VERSION ""

NS_ :

BS_:

BU_: EBCM EON CAM RADAR PCM EPS VSA SCM BDY XXX EPB

BO_ 314 THROTTLE: 8 PCM
 SG_ THROTTLE_PEDAL : 15|8@0+ (1,0) [0|255] ""  EON

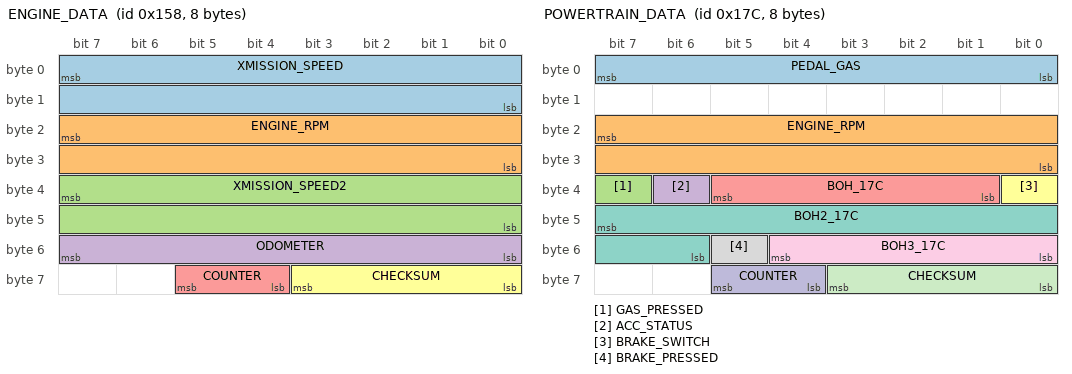
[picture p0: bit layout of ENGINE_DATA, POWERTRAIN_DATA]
BO_ 344 ENGINE_DATA: 8 PCM
 SG_ XMISSION_SPEED : 7|16@0+ (0.01,0) [0|250] "kph"  EON
 SG_ ENGINE_RPM : 23|16@0+ (1,0) [0|15000] "rpm"  EON
 SG_ XMISSION_SPEED2 : 39|16@0+ (0.01,0) [0|250] "kph"  EON
 SG_ ODOMETER : 55|8@0+ (10,0) [0|2550] "m"  XXX
 SG_ COUNTER : 61|2@0+ (1,0) [0|3] ""  EON
 SG_ CHECKSUM : 59|4@0+ (1,0) [0|15] ""  EON

BO_ 380 POWERTRAIN_DATA: 8 PCM
 SG_ PEDAL_GAS : 7|8@0+ (1,0) [0|255] ""  EON
 SG_ ENGINE_RPM : 23|16@0+ (1,0) [0|15000] "rpm"  EON
 SG_ GAS_PRESSED : 39|1@0+ (1,0) [0|1] ""  EON
 SG_ ACC_STATUS : 38|1@0+ (1,0) [0|1] ""  EON
 SG_ BOH_17C : 37|5@0+ (1,0) [0|1] ""  EON
 SG_ BRAKE_SWITCH : 32|1@0+ (1,0) [0|1] ""  EON
 SG_ BOH2_17C : 47|10@0+ (1,0) [0|1] ""  EON
 SG_ BRAKE_PRESSED : 53|1@0+ (1,0) [0|1] ""  EON
 SG_ BOH3_17C : 52|5@0+ (1,0) [0|1] ""  EON
 SG_ COUNTER : 61|2@0+ (1,0) [0|3] ""  EON
 SG_ CHECKSUM : 59|4@0+ (1,0) [0|15] ""  EON

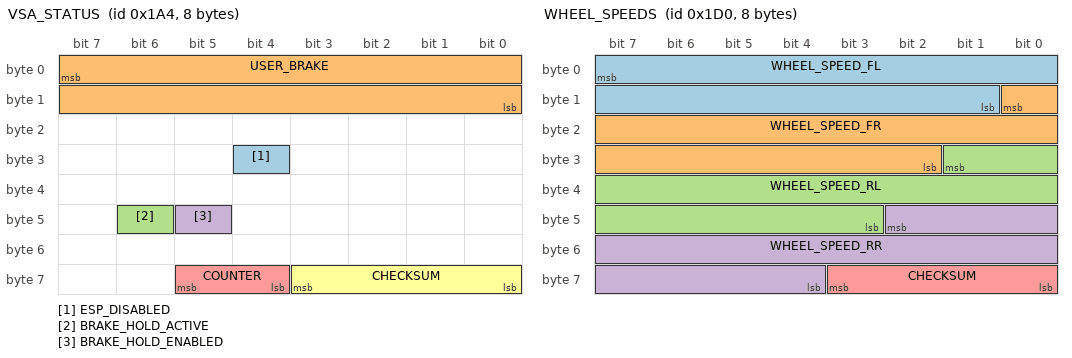
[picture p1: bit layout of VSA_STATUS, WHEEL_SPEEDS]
BO_ 420 VSA_STATUS: 8 VSA
 SG_ ESP_DISABLED : 28|1@0+ (1,0) [0|1] ""  EON
 SG_ USER_BRAKE : 7|16@0+ (0.015625,-1.609375) [0|1000] ""  EON
 SG_ BRAKE_HOLD_ACTIVE : 46|1@0+ (1,0) [0|1] ""  EON
 SG_ BRAKE_HOLD_ENABLED : 45|1@0+ (1,0) [0|1] ""  EON
 SG_ COUNTER : 61|2@0+ (1,0) [0|3] ""  EON
 SG_ CHECKSUM : 59|4@0+ (1,0) [0|15] ""  EON

BO_ 464 WHEEL_SPEEDS: 8 VSA
 SG_ WHEEL_SPEED_FL : 7|15@0+ (0.01,0) [0|250] "kph"  EON
 SG_ WHEEL_SPEED_FR : 8|15@0+ (0.01,0) [0|250] "kph"  EON
 SG_ WHEEL_SPEED_RL : 25|15@0+ (0.01,0) [0|250] "kph"  EON
 SG_ WHEEL_SPEED_RR : 42|15@0+ (0.01,0) [0|250] "kph"  EON
 SG_ CHECKSUM : 59|4@0+ (1,0) [0|3] ""  EON

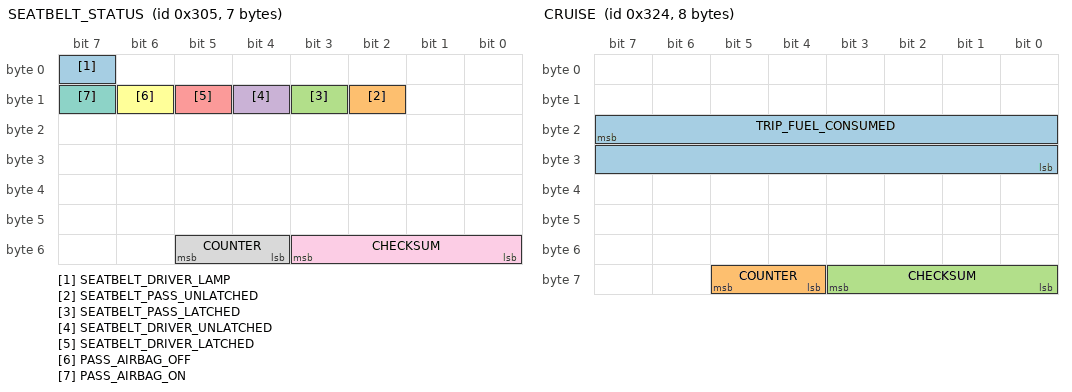
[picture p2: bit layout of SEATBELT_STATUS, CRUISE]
BO_ 773 SEATBELT_STATUS: 7 BDY
 SG_ SEATBELT_DRIVER_LAMP : 7|1@0+ (1,0) [0|1] ""  EON
 SG_ SEATBELT_PASS_UNLATCHED : 10|1@0+ (1,0) [0|1] ""  EON
 SG_ SEATBELT_PASS_LATCHED : 11|1@0+ (1,0) [0|1] ""  EON
 SG_ SEATBELT_DRIVER_UNLATCHED : 12|1@0+ (1,0) [0|1] ""  EON
 SG_ SEATBELT_DRIVER_LATCHED : 13|1@0+ (1,0) [0|1] ""  EON
 SG_ PASS_AIRBAG_OFF : 14|1@0+ (1,0) [0|1] ""  EON
 SG_ PASS_AIRBAG_ON : 15|1@0+ (1,0) [0|1] ""  EON
 SG_ COUNTER : 53|2@0+ (1,0) [0|3] ""  EON
 SG_ CHECKSUM : 51|4@0+ (1,0) [0|3] ""  EON

BO_ 804 CRUISE: 8 PCM
 SG_ TRIP_FUEL_CONSUMED : 23|16@0+ (1,0) [0|255] ""  EON
 SG_ COUNTER : 61|2@0+ (1,0) [0|3] ""  EON
 SG_ CHECKSUM : 59|4@0+ (1,0) [0|15] ""  EON

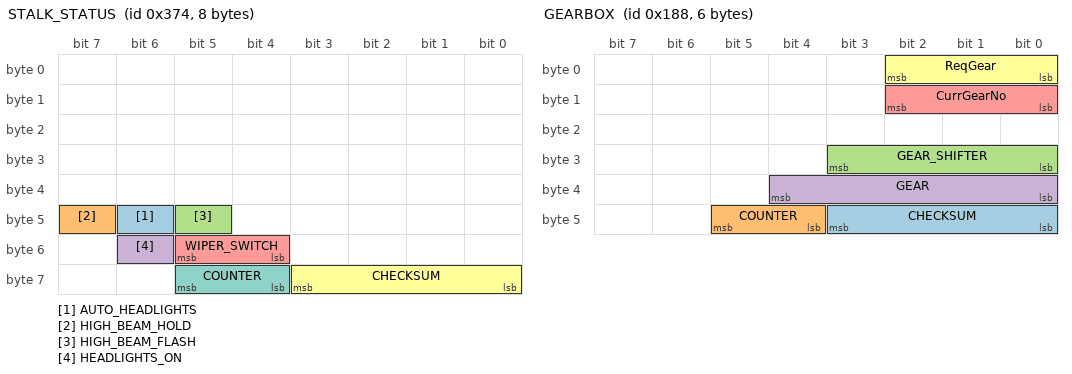
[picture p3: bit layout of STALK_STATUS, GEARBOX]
BO_ 884 STALK_STATUS: 8 XXX
 SG_ AUTO_HEADLIGHTS : 46|1@0+ (1,0) [0|1] ""  EON
 SG_ HIGH_BEAM_HOLD : 47|1@0+ (1,0) [0|1] ""  EON
 SG_ HIGH_BEAM_FLASH : 45|1@0+ (1,0) [0|1] ""  EON
 SG_ HEADLIGHTS_ON : 54|1@0+ (1,0) [0|1] ""  EON
 SG_ WIPER_SWITCH : 53|2@0+ (1,0) [0|3] ""  XXX
 SG_ CHECKSUM : 59|4@0+ (1,0) [0|3] ""  EON
 SG_ COUNTER : 61|2@0+ (1,0) [0|3] ""  EON

BO_ 392 GEARBOX: 6 XXX
 SG_ CHECKSUM : 43|4@0+ (1,0) [0|15] ""  XXX
 SG_ COUNTER : 45|2@0+ (1,0) [0|3] ""  XXX
 SG_ GEAR_SHIFTER : 27|4@0+ (1,0) [0|15] ""  EON
 SG_ GEAR : 36|5@0+ (1,0) [0|31] ""  EON
 SG_ CurrGearNo : 10|3@0+ (1,0) [0|7] "" Vector__XXX
 SG_ ReqGear : 2|3@0+ (1,0) [0|7] "" Vector__XXX

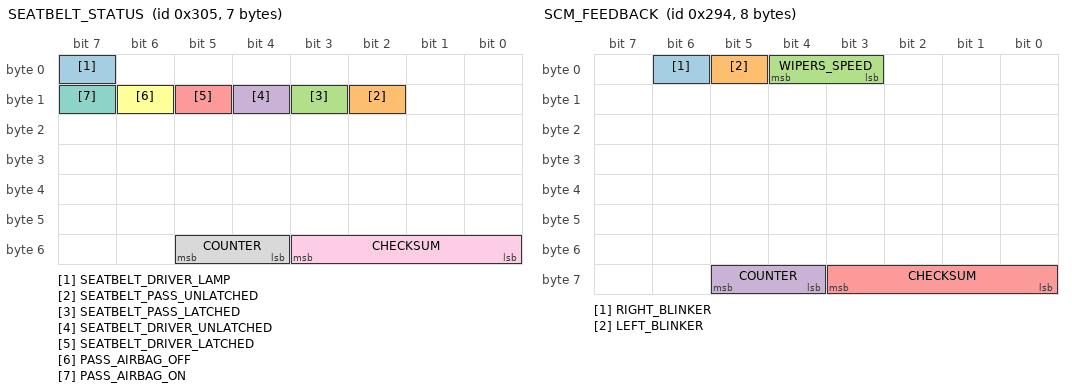
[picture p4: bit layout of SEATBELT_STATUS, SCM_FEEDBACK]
BO_ 773 SEATBELT_STATUS: 7 BDY
 SG_ SEATBELT_DRIVER_LAMP : 7|1@0+ (1,0) [0|1] ""  EON
 SG_ SEATBELT_PASS_UNLATCHED : 10|1@0+ (1,0) [0|1] ""  EON
 SG_ SEATBELT_PASS_LATCHED : 11|1@0+ (1,0) [0|1] ""  EON
 SG_ SEATBELT_DRIVER_UNLATCHED : 12|1@0+ (1,0) [0|1] ""  EON
 SG_ SEATBELT_DRIVER_LATCHED : 13|1@0+ (1,0) [0|1] ""  EON
 SG_ PASS_AIRBAG_OFF : 14|1@0+ (1,0) [0|1] ""  EON
 SG_ PASS_AIRBAG_ON : 15|1@0+ (1,0) [0|1] ""  EON
 SG_ COUNTER : 53|2@0+ (1,0) [0|3] ""  EON
 SG_ CHECKSUM : 51|4@0+ (1,0) [0|3] ""  EON

BO_ 660 SCM_FEEDBACK: 8 SCM
 SG_ RIGHT_BLINKER : 6|1@0+ (1,0) [0|1] ""  EON
 SG_ LEFT_BLINKER : 5|1@0+ (1,0) [0|1] ""  EON
 SG_ WIPERS_SPEED : 4|2@0+ (1,0) [0|3] ""  EON
 SG_ COUNTER : 61|2@0+ (1,0) [0|3] ""  EON
 SG_ CHECKSUM : 59|4@0+ (1,0) [0|15] ""  EON

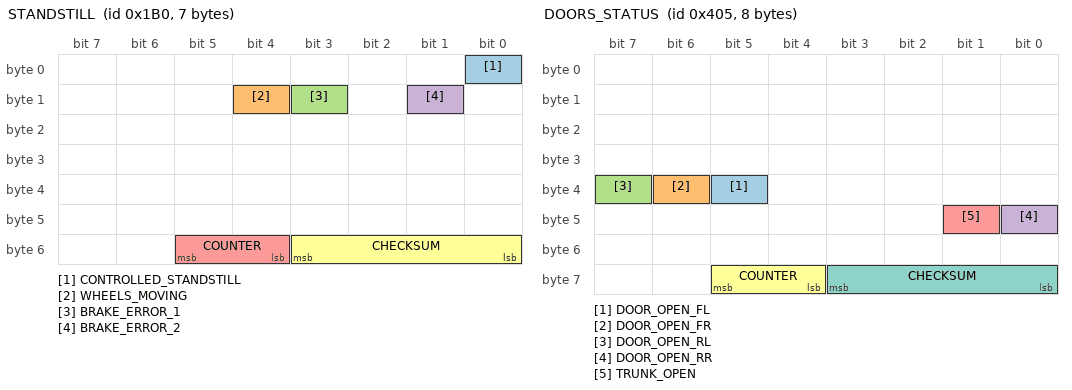
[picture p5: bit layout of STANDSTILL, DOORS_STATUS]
BO_ 432 STANDSTILL: 7 VSA
 SG_ CONTROLLED_STANDSTILL : 0|1@0+ (1,0) [0|1] ""  EON
 SG_ WHEELS_MOVING : 12|1@0+ (1,0) [0|1] ""  EON
 SG_ BRAKE_ERROR_1 : 11|1@0+ (1,0) [0|1] ""  EON
 SG_ BRAKE_ERROR_2 : 9|1@0+ (1,0) [0|1] ""  EON
 SG_ COUNTER : 53|2@0+ (1,0) [0|3] ""  EON
 SG_ CHECKSUM : 51|4@0+ (1,0) [0|3] ""  EON

BO_ 1029 DOORS_STATUS: 8 BDY
 SG_ DOOR_OPEN_FL : 37|1@0+ (1,0) [0|1] ""  EON
 SG_ DOOR_OPEN_FR : 38|1@0+ (1,0) [0|1] ""  EON
 SG_ DOOR_OPEN_RL : 39|1@0+ (1,0) [0|1] ""  EON
 SG_ DOOR_OPEN_RR : 40|1@0+ (1,0) [0|1] ""  EON
 SG_ TRUNK_OPEN : 41|1@0+ (1,0) [0|1] ""  EON
 SG_ COUNTER : 61|2@0+ (1,0) [0|3] ""  EON
 SG_ CHECKSUM : 59|4@0+ (1,0) [0|3] ""  EON

CM_ SG_ 773 PASS_AIRBAG_OFF "Might just be indicator light";
CM_ SG_ 773 PASS_AIRBAG_ON "Might just be indicator light";
VAL_ 392 GEAR_SHIFTER 0 "S" 1 "P" 2 "R" 4 "N" 8 "D" ;
VAL_ 392 GEAR 26 "S" 4 "D" 3 "N" 2 "R" 1 "P" ;
